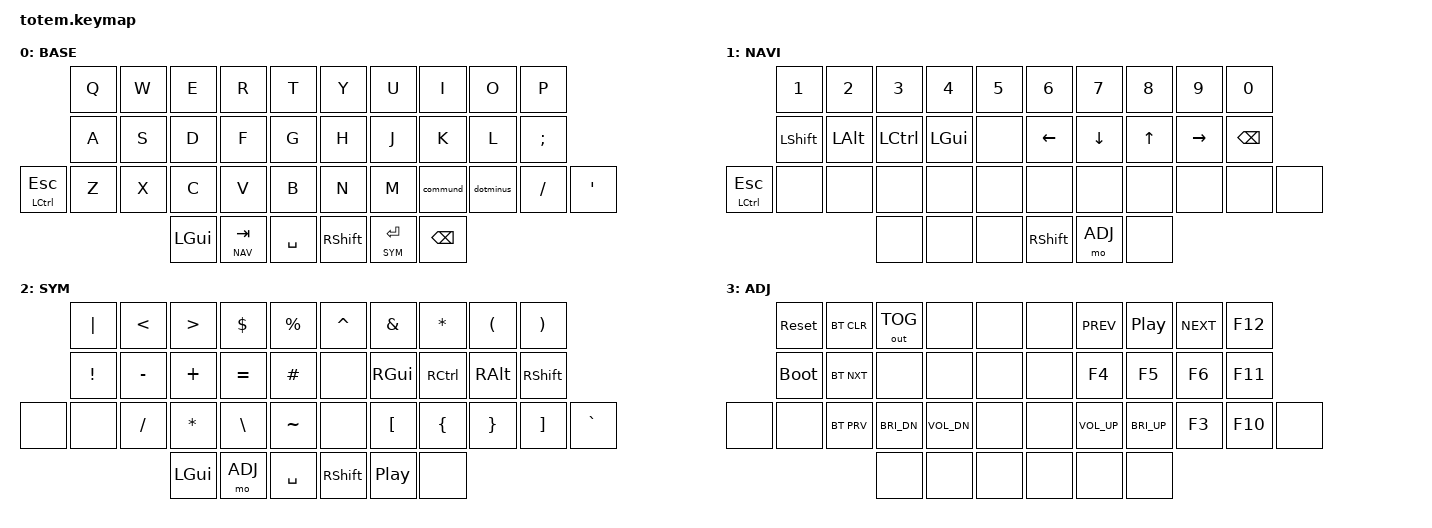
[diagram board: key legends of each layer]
//
//                                                        ▀▀▀▀▀     ▀▀▀▀▀          ▀▀█▀▀
//                                                        ▄▀▀▀▄  ▄  ▄▀▀▀▄  ▄  ▄▀▀▀▄  █  ▄▀▀▀▄
//                                                        █   █  █  █   █  █  █   █  █  █   █
//                                                         ▀▀▀   █   ▀▀▀   █   ▀▀▀   ▀   ▀▀▀
//                                                               █      ▄▄▄█▄▄▄    █   █  
//                                                               ▀      █  █  █     █▄█
//                                                             ▀▀▀▀▀    █  █  █      ▀
//                                                                      ▀  ▀  ▀
//
// ▄▄▄▄▄▄▄▄▄▄▄▄▄▄▄▄▄▄▄▄▄▄▄▄▄▄▄▄▄▄▄▄▄▄▄▄▄▄▄▄▄▄▄▄▄▄▄▄▄▄▄▄▄▄▄▄▄▄▄▄▄▄▄▄▄▄▄▄▄▄▄▄▄▄▄▄▄▄▄▄▄▄▄▄▄▄▄▄▄▄▄▄▄▄▄▄▄▄▄▄▄▄▄▄▄▄▄▄▄▄▄▄▄▄▄▄▄▄▄▄▄▄▄▄▄▄▄▄▄▄▄▄▄▄▄▄▄▄▄▄▄▄▄▄▄▄▄▄▄
       

#include <behaviors.dtsi>
#include <dt-bindings/zmk/keys.h>
#include <dt-bindings/zmk/bt.h>
#include <dt-bindings/zmk/outputs.h>

#define BASE 0
#define NAV  1
#define SYM  2
#define ADJ  3

&mt {
  flavor = "balanced";
  tapping-term-ms = <0>;
  retro-tap;
};

&lt {
  flavor = "balanced";
  tapping-term-ms = <0>;
  retro-tap;
};

/ {
     combos {
            compatible = "zmk,combos";
            combo_esc {
                timeout-ms = <50>;
                key-positions = <0 1>;
                bindings = <&kp ESC>;
            };
    };

    macros {
        gif: gif {
            label = "giphy";
            compatible = "zmk,behavior-macro";
            #binding-cells = <0>;
            bindings
                = <&macro_press &kp LSHFT>
                , <&macro_tap &kp N2>
                , <&macro_release &kp LSHFT>
                , <&macro_tap &kp G &kp I &kp F>
                ;
        };
    };

    behaviors {
        commund: comma_underscore {
            compatible = "zmk,behavior-mod-morph";
            #binding-cells = <0>;
            bindings = <&kp COMMA>, <&kp UNDER>;
            mods = <(MOD_LSFT|MOD_RSFT)>;
        };
        dotminus: dot_minus {
            compatible = "zmk,behavior-mod-morph";
            #binding-cells = <0>;
            bindings = <&kp DOT>, <&kp MINUS>;
            mods = <(MOD_LSFT|MOD_RSFT)>;
        };
    };

        keymap {
                compatible = "zmk,keymap";
// ▄▄▄▄▄▄▄▄▄▄▄▄▄▄▄▄▄▄▄▄▄▄▄▄▄▄▄▄▄▄▄▄▄▄▄▄▄▄▄▄▄▄▄▄▄▄▄▄▄▄▄▄▄▄▄▄▄▄▄▄▄▄▄▄▄▄▄▄▄▄▄▄▄▄▄▄▄▄▄▄▄▄▄▄▄▄▄▄▄▄▄▄▄▄▄▄▄▄▄▄▄▄▄▄▄▄▄▄▄▄▄▄▄▄▄▄▄▄▄▄▄▄▄▄▄▄▄▄▄▄▄▄▄▄▄▄▄▄▄▄▄▄▄▄▄▄▄▄▄

                base_layer {
// ┏━━━━━━━━━━━━━━━━━━━━━━━━━━━━━━━━━━━━━━━┓
label= "BASE"                              ;
// ┗━━━━━━━━━━━━━━━━━━━━━━━━━━━━━━━━━━━━━━━┛
//             ┏━━━━━━━━━━━┳━━━━━━━━━━━┳━━━━━━━━━━━┳━━━━━━━━━━━┳━━━━━━━━━━━┓   ┏━━━━━━━━━━━┳━━━━━━━━━━━┳━━━━━━━━━━━┳━━━━━━━━━━━┳━━━━━━━━━━━┓
//             ┃     Q     ┃     W     ┃     E     ┃     R     ┃     T     ┃   ┃     Y     ┃     U     ┃     I     ┃     O     ┃     P     ┃
//             ┣━━━━━━━━━━━╋━━━━━━━━━━━╋━━━━━━━━━━━╋━━━━━━━━━━━╋━━━━━━━━━━━┫   ┣━━━━━━━━━━━╋━━━━━━━━━━━╋━━━━━━━━━━━╋━━━━━━━━━━━╋━━━━━━━━━━━┫
//             ┃     A     ┃     S     ┃     D     ┃     F     ┃     G     ┃   ┃     H     ┃     J     ┃     K     ┃     L     ┃     ;     ┃
// ┏━━━━━━━━━━━╋━━━━━━━━━━━╋━━━━━━━━━━━╋━━━━━━━━━━━╋━━━━━━━━━━━╋━━━━━━━━━━━┫   ┣━━━━━━━━━━━╋━━━━━━━━━━━╋━━━━━━━━━━━╋━━━━━━━━━━━╋━━━━━━━━━━━╋━━━━━━━━━━━┓
// ┃   LCTRL   ┃     Z     ┃     X     ┃     C     ┃     V     ┃     B     ┃   ┃     N     ┃     M     ┃     ,     ┃     .     ┃     /     ┃     '     ┃
// ┗━━━━━━━━━━━┻━━━━━━━━━━━┻━━━━━━━━━━━╋━━━━━━━━━━━╋━━━━━━━━━━━╋━━━━━━━━━━━┫   ┣━━━━━━━━━━━╋━━━━━━━━━━━╋━━━━━━━━━━━╋━━━━━━━━━━━┻━━━━━━━━━━━┻━━━━━━━━━━━┛
//                                     ┃    LGUI   ┃    TAB    ┃    SPC    ┃   ┃   SHIFT   ┃   ENT     ┃   BSPC    ┃
//                                     ┗━━━━━━━━━━━┻━━━━━━━━━━━┻━━━━━━━━━━━┛   ┗━━━━━━━━━━━┻━━━━━━━━━━━┻━━━━━━━━━━━┛
 bindings = <
// ╷           ╷           ╷           ╷           ╷           ╷           ╷   ╷           ╷           ╷           ╷           ╷           ╷           ╷

                &kp Q       &kp W       &kp E       &kp R       &kp T           &kp Y       &kp U       &kp I       &kp O       &kp P
                &kp A       &kp S       &kp D       &kp F       &kp G           &kp H       &kp J       &kp K       &kp L       &kp SEMI
  &mt LCTRL ESC &kp Z       &kp X       &kp C       &kp V       &kp B           &kp N       &kp M       &commund   &dotminus    &kp FSLH    &kp SQT
                                        &kp LGUI   &lt NAV TAB   &kp SPACE       &kp RSHFT   &lt SYM RET   &kp BSPC
                        >;
                };

// ▄▄▄▄▄▄▄▄▄▄▄▄▄▄▄▄▄▄▄▄▄▄▄▄▄▄▄▄▄▄▄▄▄▄▄▄▄▄▄▄▄▄▄▄▄▄▄▄▄▄▄▄▄▄▄▄▄▄▄▄▄▄▄▄▄▄▄▄▄▄▄▄▄▄▄▄▄▄▄▄▄▄▄▄▄▄▄▄▄▄▄▄▄▄▄▄▄▄▄▄▄▄▄▄▄▄▄▄▄▄▄▄▄▄▄▄▄▄▄▄▄▄▄▄▄▄▄▄▄▄▄▄▄▄▄▄▄▄▄▄▄▄▄▄▄▄▄▄▄


                nav_layer {
// ┏━━━━━━━━━━━━━━━━━━━━━━━━━━━━━━━━━━━━━━━┓
label= "NAVI"                              ;
// ┗━━━━━━━━━━━━━━━━━━━━━━━━━━━━━━━━━━━━━━━┛
//             ┏━━━━━━━━━━━┳━━━━━━━━━━━┳━━━━━━━━━━━┳━━━━━━━━━━━┳━━━━━━━━━━━┓   ┏━━━━━━━━━━━┳━━━━━━━━━━━┳━━━━━━━━━━━┳━━━━━━━━━━━┳━━━━━━━━━━━┓
//             ┃     1     ┃     2     ┃     3     ┃     4     ┃     5     ┃   ┃     6     ┃     7     ┃     8     ┃     9     ┃     0     ┃
//             ┣━━━━━━━━━━━╋━━━━━━━━━━━╋━━━━━━━━━━━╋━━━━━━━━━━━╋━━━━━━━━━━━┫   ┣━━━━━━━━━━━╋━━━━━━━━━━━╋━━━━━━━━━━━╋━━━━━━━━━━━╋━━━━━━━━━━━┫
//             ┃   SHIFT   ┃    ALT    ┃    CTRL   ┃    GUI    ┃           ┃   ┃   LEFT    ┃   DOWN    ┃    UP     ┃   RIGHT   ┃   BSPC    ┃
// ┏━━━━━━━━━━━╋━━━━━━━━━━━╋━━━━━━━━━━━╋━━━━━━━━━━━╋━━━━━━━━━━━╋━━━━━━━━━━━┫   ┣━━━━━━━━━━━╋━━━━━━━━━━━╋━━━━━━━━━━━╋━━━━━━━━━━━╋━━━━━━━━━━━╋━━━━━━━━━━━┓
// ┃           ┃           ┃           ┃           ┃           ┃           ┃   ┃           ┃           ┃           ┃           ┃     b     ┃           ┃
// ┗━━━━━━━━━━━┻━━━━━━━━━━━┻━━━━━━━━━━━╋━━━━━━━━━━━╋━━━━━━━━━━━╋━━━━━━━━━━━┫   ┣━━━━━━━━━━━╋━━━━━━━━━━━╋━━━━━━━━━━━╋━━━━━━━━━━━┻━━━━━━━━━━━┻━━━━━━━━━━━┛
//                                     ┃           ┃    TAB    ┃    SPC    ┃   ┃    DEL    ┃     0     ┃           ┃
//                                     ┗━━━━━━━━━━━┻━━━━━━━━━━━┻━━━━━━━━━━━┛   ┗━━━━━━━━━━━┻━━━━━━━━━━━┻━━━━━━━━━━━┛
 bindings = <
// ╷           ╷           ╷           ╷           ╷           ╷           ╷   ╷           ╷           ╷           ╷           ╷           ╷           ╷

                &kp N1      &kp N2      &kp N3      &kp N4     &kp N5       &kp N6   &kp N7   &kp N8   &kp N9   &kp N0
                &kp LSHFT   &kp LALT    &kp LCTRL   &kp LGUI    &none           &kp LEFT    &kp DOWN    &kp UP      &kp RIGHT   &kp BSPC
  &mt LCTRL ESC &none       &none       &none       &none       &none           &none       &none       &none       &none       &none      &none       
                                        &none       &none       &none           &kp RSHFT      &mo ADJ     &none       
                        >;
                };

// ▄▄▄▄▄▄▄▄▄▄▄▄▄▄▄▄▄▄▄▄▄▄▄▄▄▄▄▄▄▄▄▄▄▄▄▄▄▄▄▄▄▄▄▄▄▄▄▄▄▄▄▄▄▄▄▄▄▄▄▄▄▄▄▄▄▄▄▄▄▄▄▄▄▄▄▄▄▄▄▄▄▄▄▄▄▄▄▄▄▄▄▄▄▄▄▄▄▄▄▄▄▄▄▄▄▄▄▄▄▄▄▄▄▄▄▄▄▄▄▄▄▄▄▄▄▄▄▄▄▄▄▄▄▄▄▄▄▄▄▄▄▄▄▄▄▄▄▄▄


                sim_layer {
// ┏━━━━━━━━━━━━━━━━━━━━━━━━━━━━━━━━━━━━━━━┓
label= "SYM"                               ;
// ┗━━━━━━━━━━━━━━━━━━━━━━━━━━━━━━━━━━━━━━━┛
//             ┏━━━━━━━━━━━┳━━━━━━━━━━━┳━━━━━━━━━━━┳━━━━━━━━━━━┳━━━━━━━━━━━┓   ┏━━━━━━━━━━━┳━━━━━━━━━━━┳━━━━━━━━━━━┳━━━━━━━━━━━┳━━━━━━━━━━━┓
//             ┃     !     ┃     @     ┃     #     ┃     $     ┃     %     ┃   ┃     ˆ     ┃     &     ┃     Ü     ┃     '     ┃     "     ┃
//             ┣━━━━━━━━━━━╋━━━━━━━━━━━╋━━━━━━━━━━━╋━━━━━━━━━━━╋━━━━━━━━━━━┫   ┣━━━━━━━━━━━╋━━━━━━━━━━━╋━━━━━━━━━━━╋━━━━━━━━━━━╋━━━━━━━━━━━┫
//             ┃     Ä     ┃           ┃    SZ     ┃           ┃           ┃   ┃   MUTE    ┃   YEN     ┃   EURO    ┃  POUND    ┃     Ö     ┃
// ┏━━━━━━━━━━━╋━━━━━━━━━━━╋━━━━━━━━━━━╋━━━━━━━━━━━╋━━━━━━━━━━━╋━━━━━━━━━━━┫   ┣━━━━━━━━━━━╋━━━━━━━━━━━╋━━━━━━━━━━━╋━━━━━━━━━━━╋━━━━━━━━━━━╋━━━━━━━━━━━┓
// ┃           ┃  EMAIL1   ┃  EMAIL2   ┃           ┃           ┃           ┃   ┃   VOL-    ┃   VOL+    ┃   LAST    ┃   NEXT    ┃     \     ┃           ┃
// ┗━━━━━━━━━━━┻━━━━━━━━━━━┻━━━━━━━━━━━╋━━━━━━━━━━━╋━━━━━━━━━━━╋━━━━━━━━━━━┫   ┣━━━━━━━━━━━╋━━━━━━━━━━━╋━━━━━━━━━━━╋━━━━━━━━━━━┻━━━━━━━━━━━┻━━━━━━━━━━━┛
//                                     ┃           ┃    GIF    ┃    ADJ    ┃   ┃           ┃           ┃           ┃
//                                     ┗━━━━━━━━━━━┻━━━━━━━━━━━┻━━━━━━━━━━━┛   ┗━━━━━━━━━━━┻━━━━━━━━━━━┻━━━━━━━━━━━┛
 bindings = <
// ╷           ╷           ╷           ╷           ╷           ╷           ╷   ╷           ╷           ╷           ╷           ╷           ╷           ╷

                &kp PIPE   &kp LT       &kp  GT   &kp DLLR    &kp PRCNT       &kp CARET   &kp AMPS    &kp ASTRK   &kp LPAR     &kp RPAR       
                &kp EXCL   &kp MINUS    &kp PLUS    &kp EQUAL   &kp HASH        &none    &kp RGUI    &kp RCTRL   &kp RALT     &kp RSHFT
    &none       &none      &kp FSLH    &kp ASTRK    &kp BSLH    &kp TILDE       &none    &kp LBKT   &kp LBRC     &kp RBRC     &kp RBKT   &kp GRAVE         
                                        &kp LGUI      &mo ADJ     &kp SPACE     &kp RSHFT      &kp C_PP    &none       
                        >;
                };

// ▄▄▄▄▄▄▄▄▄▄▄▄▄▄▄▄▄▄▄▄▄▄▄▄▄▄▄▄▄▄▄▄▄▄▄▄▄▄▄▄▄▄▄▄▄▄▄▄▄▄▄▄▄▄▄▄▄▄▄▄▄▄▄▄▄▄▄▄▄▄▄▄▄▄▄▄▄▄▄▄▄▄▄▄▄▄▄▄▄▄▄▄▄▄▄▄▄▄▄▄▄▄▄▄▄▄▄▄▄▄▄▄▄▄▄▄▄▄▄▄▄▄▄▄▄▄▄▄▄▄▄▄▄▄▄▄▄▄▄▄▄▄▄▄▄▄▄▄▄


                adjust_layer {
// ┏━━━━━━━━━━━━━━━━━━━━━━━━━━━━━━━━━━━━━━━┓
label= "ADJ"                               ;
// ┗━━━━━━━━━━━━━━━━━━━━━━━━━━━━━━━━━━━━━━━┛
//             ┏━━━━━━━━━━━┳━━━━━━━━━━━┳━━━━━━━━━━━┳━━━━━━━━━━━┳━━━━━━━━━━━┓   ┏━━━━━━━━━━━┳━━━━━━━━━━━┳━━━━━━━━━━━┳━━━━━━━━━━━┳━━━━━━━━━━━┓
//             ┃   RESET   ┃ BT CLEAR  ┃  OUT TOG  ┃           ┃           ┃   ┃           ┃    F7     ┃    F8     ┃    F9     ┃    F12    ┃
//             ┣━━━━━━━━━━━╋━━━━━━━━━━━╋━━━━━━━━━━━╋━━━━━━━━━━━╋━━━━━━━━━━━┫   ┣━━━━━━━━━━━╋━━━━━━━━━━━╋━━━━━━━━━━━╋━━━━━━━━━━━╋━━━━━━━━━━━┫
//             ┃ BOOTLOAD  ┃ BT NEXT   ┃           ┃           ┃           ┃   ┃           ┃    F4     ┃    F5     ┃    F6     ┃    F11    ┃
// ┏━━━━━━━━━━━╋━━━━━━━━━━━╋━━━━━━━━━━━╋━━━━━━━━━━━╋━━━━━━━━━━━╋━━━━━━━━━━━┫   ┣━━━━━━━━━━━╋━━━━━━━━━━━╋━━━━━━━━━━━╋━━━━━━━━━━━╋━━━━━━━━━━━╋━━━━━━━━━━━┓
// ┃           ┃           ┃ BT PREV   ┃           ┃           ┃           ┃   ┃           ┃    F1     ┃    F2     ┃    F3     ┃    F10    ┃           ┃
// ┗━━━━━━━━━━━┻━━━━━━━━━━━┻━━━━━━━━━━━╋━━━━━━━━━━━╋━━━━━━━━━━━╋━━━━━━━━━━━┫   ┣━━━━━━━━━━━╋━━━━━━━━━━━╋━━━━━━━━━━━╋━━━━━━━━━━━┻━━━━━━━━━━━┻━━━━━━━━━━━┛
//                                     ┃           ┃           ┃           ┃   ┃           ┃           ┃           ┃
//                                     ┗━━━━━━━━━━━┻━━━━━━━━━━━┻━━━━━━━━━━━┛   ┗━━━━━━━━━━━┻━━━━━━━━━━━┻━━━━━━━━━━━┛
 bindings = <
// ╷           ╷           ╷           ╷           ╷           ╷           ╷   ╷           ╷           ╷           ╷           ╷           ╷           ╷

                &sys_reset  &bt BT_CLR &out OUT_TOG &none       &none           &none       &kp C_PREV      &kp C_PP      &kp C_NEXT      &kp F12
                &bootloader &bt BT_NXT  &none       &none       &none           &none       &kp F4      &kp F5      &kp F6      &kp F11  
    &none       &none       &bt BT_PRV  &kp C_BRI_DN&kp C_VOL_DN&none           &none       &kp C_VOL_UP&kp C_BRI_UP&kp F3      &kp F10     &none          
                                        &none       &none       &none           &none       &none       &none       
                        >;
                };
        };
};
